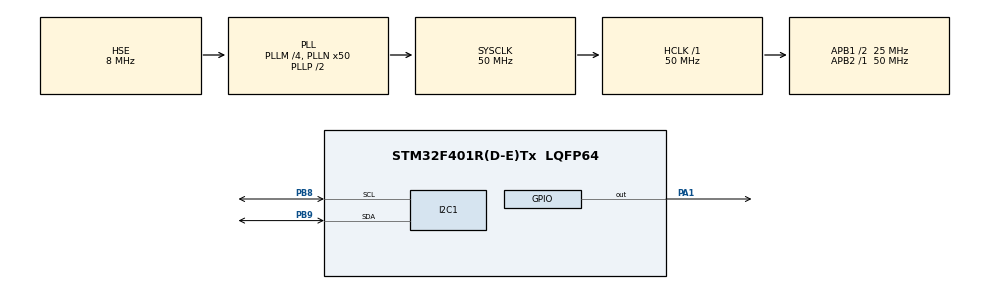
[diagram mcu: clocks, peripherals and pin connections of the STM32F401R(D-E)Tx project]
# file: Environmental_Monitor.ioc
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Mcu.Family=STM32F4
Mcu.Name=STM32F401R(D-E)Tx
Mcu.Package=LQFP64
NVIC.PriorityGroup=NVIC_PRIORITYGROUP_4
PA1.Signal=GPIO_Output
PB8.Mode=I2C
PB8.Signal=I2C1_SCL
PB9.Mode=I2C
PB9.Signal=I2C1_SDA
PH0\ -\ OSC_IN.Mode=HSE-External-Oscillator
PH0\ -\ OSC_IN.Signal=RCC_OSC_IN
PH1\ -\ OSC_OUT.Mode=HSE-External-Oscillator
PH1\ -\ OSC_OUT.Signal=RCC_OSC_OUT
ProjectManager.HeapSize=0x200
ProjectManager.StackSize=0x400
ProjectManager.TargetToolchain=STM32CubeIDE
RCC.48MHZClocksFreq_Value=25000000
RCC.AHBFreq_Value=50000000
RCC.APB1CLKDivider=RCC_HCLK_DIV2
RCC.APB1Freq_Value=25000000
RCC.APB1TimFreq_Value=50000000
RCC.APB2Freq_Value=50000000
RCC.APB2TimFreq_Value=50000000
RCC.CortexFreq_Value=50000000
RCC.HCLKFreq_Value=50000000
RCC.HSE_VALUE=8000000
RCC.HSI_VALUE=16000000
RCC.LSE_VALUE=32768
RCC.PLLM=4
RCC.PLLN=50
RCC.PLLSourceVirtual=RCC_PLLSOURCE_HSE
RCC.SYSCLKFreq_VALUE=50000000
RCC.SYSCLKSource=RCC_SYSCLKSOURCE_PLLCLK
RCC.VCOOutputFreq_Value=100000000
TIM10.Period=0xffff-1
TIM10.Prescaler=50-1
VP_TIM10_VS_ClockSourceINT.Mode=Enable_Timer
board=custom

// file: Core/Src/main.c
/* USER CODE BEGIN Header */
/**
  ******************************************************************************
  * @file           : main.c
  * @brief          : Main program body
  ******************************************************************************
  * @attention
  *
  * Copyright (c) 2025 STMicroelectronics.
  * All rights reserved.
  *
  * This software is licensed under terms that can be found in the LICENSE file
  * in the root directory of this software component.
  * If no LICENSE file comes with this software, it is provided AS-IS.
  *
  ******************************************************************************
  */
/* USER CODE END Header */
#include "main.h"

/* USER CODE BEGIN Includes */

#include "i2c_lcd.h"
#include "stdio.h"

/* USER CODE END Includes */

I2C_HandleTypeDef hi2c1;

TIM_HandleTypeDef htim10;

void SystemClock_Config(void);
static void MX_GPIO_Init(void);
static void MX_I2C1_Init(void);
static void MX_TIM10_Init(void);

/* USER CODE BEGIN 0 */

// Variables
uint8_t Rh_byte1, Rh_byte2, Temp_byte1, Temp_byte2;
uint16_t SUM, RH, TEMP;

float Temperature = 0;
float Humidity = 0;
uint8_t Presence = 0;

I2C_HandleTypeDef hi2c1;
I2C_LCD_HandleTypeDef lcd1;

// Functions
void delay (uint16_t us)
{
	__HAL_TIM_SET_COUNTER(&htim10, 0); // Set counter value to 0
	while (__HAL_TIM_GET_COUNTER(&htim10) < us);
	// ^ Waits for the counter to reach the us input in the parameter
}

void Display_Temp (float temperature)
{
	char temp_str[16];
	sprintf(temp_str, "TEMP: %.2f C", temperature);
	lcd_gotoxy(&lcd1, 0, 0); // Move cursor to the first row, first column
	lcd_puts(&lcd1, temp_str);
}

void Display_Rh (float humidity)
{
	char rh_str[16];
	sprintf(rh_str, "RH: %.2f %%", humidity);
	lcd_gotoxy(&lcd1, 0, 1); // Move cursor to the second row, first column
	lcd_puts(&lcd1, rh_str);
}

void Set_Pin_Output(GPIO_TypeDef *GPIOx, uint16_t GPIO_PIN)
{
	GPIO_InitTypeDef GPIO_InitStruct = {0};
	GPIO_InitStruct.Pin = GPIO_PIN;
	GPIO_InitStruct.Mode = GPIO_MODE_OUTPUT_PP;
	GPIO_InitStruct.Speed = GPIO_SPEED_FREQ_LOW;
	HAL_GPIO_Init(GPIOx, &GPIO_InitStruct);
}

void Set_Pin_Input(GPIO_TypeDef *GPIOx, uint16_t GPIO_PIN)
{
	GPIO_InitTypeDef GPIO_InitStruct = {0};
	GPIO_InitStruct.Pin = GPIO_PIN;
	GPIO_InitStruct.Mode = GPIO_MODE_INPUT;
	GPIO_InitStruct.Pull = GPIO_PULLUP;
	HAL_GPIO_Init(GPIOx, &GPIO_InitStruct);
}

// DHT11 Functions
#define DHT11_PORT GPIOA
#define DHT11_PIN GPIO_PIN_1

void DHT11_Start (void)
{
	Set_Pin_Output(DHT11_PORT, DHT11_PIN); // Set pin as output
	HAL_GPIO_WritePin(DHT11_PORT, DHT11_PIN, 0); // Pull pin low
	delay(18000); // Wait for 18ms
	HAL_GPIO_WritePin(DHT11_PORT, DHT11_PIN, 1); // Pull the pin high
	delay(20); // Wait for 20us
	Set_Pin_Input(DHT11_PORT, DHT11_PIN); // Set as input
}

uint8_t DHT11_Check_Response (void)
{
	uint8_t Response = 0;
	delay(40); // Wait 40us
	if ((!HAL_GPIO_ReadPin(DHT11_PORT, DHT11_PIN))) // Checks if pin is low
	{
		delay(80); // Wait 80us
		if ((HAL_GPIO_ReadPin(DHT11_PORT, DHT11_PIN))) Response = 1; // Check if pin is high
		else Response = -1; // Sensor is not present/invalid response
	}
	while ((HAL_GPIO_ReadPin(DHT11_PORT, DHT11_PIN))); // Wait for pin to go low

	return Response;
}

uint8_t DHT11_Read (void)
{
	uint8_t i,j;
	for (j=0; j<8; j++) // Reads a 8 bit data byte
	{
		while ((!HAL_GPIO_ReadPin(DHT11_PORT, DHT11_PIN))); // Wait for pin to go high
		delay(40); // Wait for 40us
		if ((!HAL_GPIO_ReadPin(DHT11_PORT, DHT11_PIN))) // Pin is low
		{
			i &= ~(1 << (7-j)); // Write 0 (bit at the jth position will be forced to 0 by & operator)
		}
		else i |= (1<< (7-j)); // Write 1 when pin is high (bit is forced to 1 by | operator)
		while ((HAL_GPIO_ReadPin(DHT11_PORT, DHT11_PIN))); // Wait for pin to go back low
	}
	return i;
}

/* USER CODE END 0 */

int main(void)
{

  /* MCU Configuration--------------------------------------------------------*/

  /* Reset of all peripherals, Initializes the Flash interface and the Systick. */
  HAL_Init();

  /* Configure the system clock */
  SystemClock_Config();

  /* Initialize all configured peripherals */
  MX_GPIO_Init();
  MX_I2C1_Init();
  MX_TIM10_Init();
  /* USER CODE BEGIN 2 */

  HAL_TIM_Base_Start(&htim10);

  lcd1.hi2c = &hi2c1;
  lcd1.address = (0x27 << 1);
  lcd_init(&lcd1);
  lcd_clear(&lcd1);
  lcd_puts(&lcd1, "Initializing");
  lcd_gotoxy(&lcd1, 0, 1);
  lcd_puts(&lcd1, "Monitor...");
  HAL_Delay(3000);
  lcd_clear(&lcd1);

  /* USER CODE END 2 */

  /* Infinite loop */
  while (1)
  {

    /* USER CODE BEGIN 3 */
	  // Display data on LCD
	  Display_Temp(Temperature);
	  Display_Rh(Humidity);

	  // Start DHT11 interface and check for response
	  DHT11_Start();
	  Presence = DHT11_Check_Response();

	  // Read all 5 bytes(40 bits) of the data the sensor sends
	  Rh_byte1 = DHT11_Read();
	  Rh_byte2 = DHT11_Read();
	  Temp_byte1 = DHT11_Read();
	  Temp_byte2 = DHT11_Read();
	  SUM = DHT11_Read();

	  TEMP = Temp_byte1;
	  RH = Rh_byte1;
	  Temperature = (float) TEMP;
	  Humidity = (float) RH;
	  HAL_Delay(1000);
  }
  /* USER CODE END 3 */
}

void SystemClock_Config(void)
{
  RCC_OscInitTypeDef RCC_OscInitStruct = {0};
  RCC_ClkInitTypeDef RCC_ClkInitStruct = {0};

  /** Configure the main internal regulator output voltage
  */
  __HAL_RCC_PWR_CLK_ENABLE();
  __HAL_PWR_VOLTAGESCALING_CONFIG(PWR_REGULATOR_VOLTAGE_SCALE2);

  /** Initializes the RCC Oscillators according to the specified parameters
  * in the RCC_OscInitTypeDef structure.
  */
  RCC_OscInitStruct.OscillatorType = RCC_OSCILLATORTYPE_HSE;
  RCC_OscInitStruct.HSEState = RCC_HSE_ON;
  RCC_OscInitStruct.PLL.PLLState = RCC_PLL_ON;
  RCC_OscInitStruct.PLL.PLLSource = RCC_PLLSOURCE_HSE;
  RCC_OscInitStruct.PLL.PLLM = 4;
  RCC_OscInitStruct.PLL.PLLN = 50;
  RCC_OscInitStruct.PLL.PLLP = RCC_PLLP_DIV2;
  RCC_OscInitStruct.PLL.PLLQ = 4;
  if (HAL_RCC_OscConfig(&RCC_OscInitStruct) != HAL_OK)
  {
    Error_Handler();
  }

  /** Initializes the CPU, AHB and APB buses clocks
  */
  RCC_ClkInitStruct.ClockType = RCC_CLOCKTYPE_HCLK|RCC_CLOCKTYPE_SYSCLK
                              |RCC_CLOCKTYPE_PCLK1|RCC_CLOCKTYPE_PCLK2;
  RCC_ClkInitStruct.SYSCLKSource = RCC_SYSCLKSOURCE_PLLCLK;
  RCC_ClkInitStruct.AHBCLKDivider = RCC_SYSCLK_DIV1;
  RCC_ClkInitStruct.APB1CLKDivider = RCC_HCLK_DIV2;
  RCC_ClkInitStruct.APB2CLKDivider = RCC_HCLK_DIV1;

  if (HAL_RCC_ClockConfig(&RCC_ClkInitStruct, FLASH_LATENCY_1) != HAL_OK)
  {
    Error_Handler();
  }
}

static void MX_I2C1_Init(void)
{

  hi2c1.Instance = I2C1;
  hi2c1.Init.ClockSpeed = 100000;
  hi2c1.Init.DutyCycle = I2C_DUTYCYCLE_2;
  hi2c1.Init.OwnAddress1 = 0;
  hi2c1.Init.AddressingMode = I2C_ADDRESSINGMODE_7BIT;
  hi2c1.Init.DualAddressMode = I2C_DUALADDRESS_DISABLE;
  hi2c1.Init.OwnAddress2 = 0;
  hi2c1.Init.GeneralCallMode = I2C_GENERALCALL_DISABLE;
  hi2c1.Init.NoStretchMode = I2C_NOSTRETCH_DISABLE;
  if (HAL_I2C_Init(&hi2c1) != HAL_OK)
  {
    Error_Handler();
  }

}

static void MX_TIM10_Init(void)
{

  htim10.Instance = TIM10;
  htim10.Init.Prescaler = 50-1;
  htim10.Init.CounterMode = TIM_COUNTERMODE_UP;
  htim10.Init.Period = 65535;
  htim10.Init.ClockDivision = TIM_CLOCKDIVISION_DIV1;
  htim10.Init.AutoReloadPreload = TIM_AUTORELOAD_PRELOAD_DISABLE;
  if (HAL_TIM_Base_Init(&htim10) != HAL_OK)
  {
    Error_Handler();
  }

}

static void MX_GPIO_Init(void)
{
  GPIO_InitTypeDef GPIO_InitStruct = {0};

  /* GPIO Ports Clock Enable */
  __HAL_RCC_GPIOH_CLK_ENABLE();
  __HAL_RCC_GPIOA_CLK_ENABLE();
  __HAL_RCC_GPIOB_CLK_ENABLE();

  /*Configure GPIO pin Output Level */
  HAL_GPIO_WritePin(GPIOA, GPIO_PIN_1, GPIO_PIN_RESET);

  /*Configure GPIO pin : PA1 */
  GPIO_InitStruct.Pin = GPIO_PIN_1;
  GPIO_InitStruct.Mode = GPIO_MODE_OUTPUT_PP;
  GPIO_InitStruct.Pull = GPIO_NOPULL;
  GPIO_InitStruct.Speed = GPIO_SPEED_FREQ_LOW;
  HAL_GPIO_Init(GPIOA, &GPIO_InitStruct);

}

void Error_Handler(void)
{
  __disable_irq();
  while (1)
  {
  }
}
